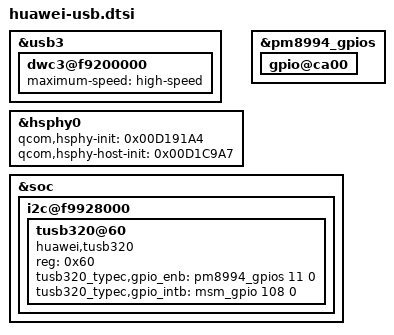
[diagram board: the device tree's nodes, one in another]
/* Copyright (c) 2014-2015, The Linux Foundation. All rights reserved.
 *
 * This program is free software; you can redistribute it and/or modify
 * it under the terms of the GNU General Public License version 2 and
 * only version 2 as published by the Free Software Foundation.
 *
 * This program is distributed in the hope that it will be useful,
 * but WITHOUT ANY WARRANTY; without even the implied warranty of
 * MERCHANTABILITY or FITNESS FOR A PARTICULAR PURPOSE.  See the
 * GNU General Public License for more details.
 */

&usb3 {
	dwc3@f9200000 {
		maximum-speed = "high-speed";
	};
};

&hsphy0 {
	qcom,hsphy-init = <0x00D191A4>;
	qcom,hsphy-host-init = <0x00D1C9A7>;
};

&pm8994_gpios {
	gpio@ca00 { /* GPIO 11 */
		status = "ok";
	};
};

&soc {
	/* BLSP1 QUP6 */
	i2c@f9928000 {
		status = "ok";
		tusb320@60 {
			compatible = "huawei,tusb320";
			reg = <0x60>;
			tusb320_typec,gpio_enb = <&pm8994_gpios 11 0>;
			tusb320_typec,gpio_intb = <&msm_gpio 108 0>;
		};
	};
};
